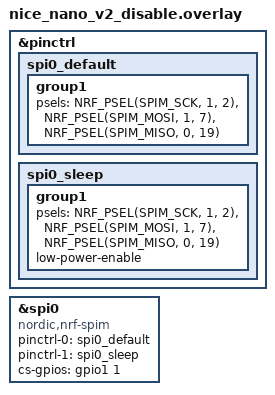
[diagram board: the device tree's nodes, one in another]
&pinctrl {
    spi0_default: spi0_default {
        group1 {
            psels = <NRF_PSEL(SPIM_SCK, 1, 2)>,
                <NRF_PSEL(SPIM_MOSI, 1, 7)>,
                <NRF_PSEL(SPIM_MISO, 0, 19)>;
        };
    };
    spi0_sleep: spi0_sleep {
        group1 {
            psels = <NRF_PSEL(SPIM_SCK, 1, 2)>,
                <NRF_PSEL(SPIM_MOSI, 1, 7)>,
                <NRF_PSEL(SPIM_MISO, 0, 19)>;
            low-power-enable;
        };
    };
};

nice_view_spi: &spi0 {
    compatible = "nordic,nrf-spim";
    pinctrl-0 = <&spi0_default>;
    pinctrl-1 = <&spi0_sleep>;
    pinctrl-names = "default", "sleep";
    cs-gpios = <&gpio1 1 0>;
};
